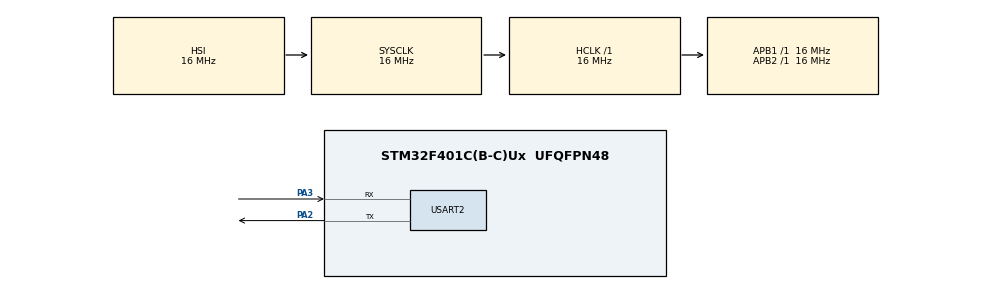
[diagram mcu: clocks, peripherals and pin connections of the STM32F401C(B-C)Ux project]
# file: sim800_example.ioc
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Mcu.Family=STM32F4
Mcu.Name=STM32F401C(B-C)Ux
Mcu.Package=UFQFPN48
NVIC.PriorityGroup=NVIC_PRIORITYGROUP_4
NVIC.USART2_IRQn=true\:0\:0\:false\:false\:true\:true\:true\:true
PA2.Mode=Asynchronous
PA2.Signal=USART2_TX
PA3.Mode=Asynchronous
PA3.Signal=USART2_RX
ProjectManager.HeapSize=0x200
ProjectManager.StackSize=0x400
ProjectManager.TargetToolchain=STM32CubeIDE
RCC.AHBFreq_Value=16000000
RCC.APB1Freq_Value=16000000
RCC.APB2Freq_Value=16000000
RCC.CortexFreq_Value=16000000
RCC.HSE_VALUE=25000000
RCC.HSI_VALUE=16000000
RCC.LSE_VALUE=32768
RCC.SYSCLKFreq_VALUE=16000000
RCC.VCOOutputFreq_Value=192000000
USART2.VirtualMode=VM_ASYNC
board=custom

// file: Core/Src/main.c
/* USER CODE BEGIN Header */
/**
  ******************************************************************************
  * @file           : main.c
  * @brief          : Main program body
  ******************************************************************************
  * @attention
  *
  * Copyright (c) 2023 STMicroelectronics.
  * All rights reserved.
  *
  * This software is licensed under terms that can be found in the LICENSE file
  * in the root directory of this software component.
  * If no LICENSE file comes with this software, it is provided AS-IS.
  *
  ******************************************************************************
  */
/* USER CODE END Header */
#include "main.h"

/* USER CODE BEGIN Includes */
#include <string.h>
#include <stdio.h>
#include "sim800.h"
/* USER CODE END Includes */

/* USER CODE BEGIN PD */

#define PHONE_NUMBER				"************"

/* USER CODE END PD */

UART_HandleTypeDef huart2;

/* USER CODE BEGIN PV */

UART_HandleTypeDef *sim800_uart = &huart2;

SIM800_Handle_t sim800h = {0};

uint8_t flag = 0;
char sms_buff[100];

/* USER CODE END PV */

void SystemClock_Config(void);
static void MX_GPIO_Init(void);
static void MX_USART2_UART_Init(void);

int main(void)
{

  /* MCU Configuration--------------------------------------------------------*/

  /* Reset of all peripherals, Initializes the Flash interface and the Systick. */
  HAL_Init();

  /* Configure the system clock */
  SystemClock_Config();

  /* Initialize all configured peripherals */
  MX_GPIO_Init();
  MX_USART2_UART_Init();
  /* USER CODE BEGIN 2 */
    SIM800_Battery_t battery = {0};
    char tx_buff[100];

    //Start receiving data from module
	if( SIM800_ManageReceiving(&sim800h, ENABLE) != SIM800_OK )
	{
		Error_Handler();
	}

	//Wait for sim800 registration in network. Do a little break while iterating.
  	while( SIM800_GetNetworkRegStatus(&sim800h) != SIM800_Registered_HomeNetwork &&
  		   SIM800_GetNetworkRegStatus(&sim800h) != SIM800_Registered_Roaming)
	{
  		HAL_Delay(500);
	}

	//Delete all exists SMS messages to free memory
	if( SIM800_DeleteAllSMSMessages(&sim800h) != SIM800_OK )
	{
		Error_Handler();
	}

	//Set SMS text mode
	if( SIM800_SetSMSTextMode(&sim800h) != SIM800_OK )
	{
		Error_Handler();
	}

	//Enable SMS notifications callback
	if( SIM800_ManageSMSNotifications(&sim800h, ENABLE) != SIM800_OK )
	{
		Error_Handler();
	}

	//Send initial SMS message
	if( SIM800_SendSMSMessage(&sim800h, PHONE_NUMBER, "Ready!") != SIM800_OK )
	{
		Error_Handler();
	}

  /* USER CODE END 2 */

  /* Infinite loop */
  while (1)
  {

	  //Check if MCU received new message
	  if(flag)
	  {
		  //If received message text is "Batt" receive information about battery and send it.
		  if( !strcmp(sms_buff, "Batt") )
		  {
			  SIM800_GetBatteryInfo(&sim800h, &battery);

			  sprintf(tx_buff, "Battery level: %d\r\nConnection level: %d", battery.battery_level, battery.conection_level);

			  SIM800_SendSMSMessage(&sim800h, PHONE_NUMBER, tx_buff);
		  } else
		  {
			  SIM800_SendSMSMessage(&sim800h, PHONE_NUMBER, "Unknown command!!!");
		  }
		  flag = 0;
	  }

  }
}

void SystemClock_Config(void)
{
  RCC_OscInitTypeDef RCC_OscInitStruct = {0};
  RCC_ClkInitTypeDef RCC_ClkInitStruct = {0};

  /** Configure the main internal regulator output voltage
  */
  __HAL_RCC_PWR_CLK_ENABLE();
  __HAL_PWR_VOLTAGESCALING_CONFIG(PWR_REGULATOR_VOLTAGE_SCALE2);

  /** Initializes the RCC Oscillators according to the specified parameters
  * in the RCC_OscInitTypeDef structure.
  */
  RCC_OscInitStruct.OscillatorType = RCC_OSCILLATORTYPE_HSI;
  RCC_OscInitStruct.HSIState = RCC_HSI_ON;
  RCC_OscInitStruct.HSICalibrationValue = RCC_HSICALIBRATION_DEFAULT;
  RCC_OscInitStruct.PLL.PLLState = RCC_PLL_NONE;
  if (HAL_RCC_OscConfig(&RCC_OscInitStruct) != HAL_OK)
  {
    Error_Handler();
  }

  /** Initializes the CPU, AHB and APB buses clocks
  */
  RCC_ClkInitStruct.ClockType = RCC_CLOCKTYPE_HCLK|RCC_CLOCKTYPE_SYSCLK
                              |RCC_CLOCKTYPE_PCLK1|RCC_CLOCKTYPE_PCLK2;
  RCC_ClkInitStruct.SYSCLKSource = RCC_SYSCLKSOURCE_HSI;
  RCC_ClkInitStruct.AHBCLKDivider = RCC_SYSCLK_DIV1;
  RCC_ClkInitStruct.APB1CLKDivider = RCC_HCLK_DIV1;
  RCC_ClkInitStruct.APB2CLKDivider = RCC_HCLK_DIV1;

  if (HAL_RCC_ClockConfig(&RCC_ClkInitStruct, FLASH_LATENCY_0) != HAL_OK)
  {
    Error_Handler();
  }
}

static void MX_USART2_UART_Init(void)
{

  huart2.Instance = USART2;
  huart2.Init.BaudRate = 115200;
  huart2.Init.WordLength = UART_WORDLENGTH_8B;
  huart2.Init.StopBits = UART_STOPBITS_1;
  huart2.Init.Parity = UART_PARITY_NONE;
  huart2.Init.Mode = UART_MODE_TX_RX;
  huart2.Init.HwFlowCtl = UART_HWCONTROL_NONE;
  huart2.Init.OverSampling = UART_OVERSAMPLING_16;
  if (HAL_UART_Init(&huart2) != HAL_OK)
  {
    Error_Handler();
  }

}

static void MX_GPIO_Init(void)
{

  /* GPIO Ports Clock Enable */
  __HAL_RCC_GPIOA_CLK_ENABLE();

}

/* USER CODE BEGIN 4 */

void HAL_UART_RxCpltCallback(UART_HandleTypeDef *huart)
{
	if(huart == sim800_uart)
	{
		SIM800_MessageHandler(&sim800h);
	}
}

void SIM800_NewSMSNotificationCallBack(SIM800_Handle_t *handle, uint32_t sms_index)
{
	SIM800_RequestSMSMessage(handle, sms_index);
}

void SIM800_RcvdSMSCallBack(SIM800_Handle_t *handle, SIM800_SMSMessage_t *message)
{
	strcpy(sms_buff, message->text);

	flag = 1;
}

/* USER CODE END 4 */

void Error_Handler(void)
{
  __disable_irq();
  while (1)
  {
  }
}
